AUTOSAR XML (schema 00049)
package /PerceptionApp
  process design PerceptionDesign: executable=perceptiond
package /PerceptionApp/exe
  executable perceptiond: category=APPLICATION_LEVEL, logging-behavior=USES-LOGGING, reporting-behavior=REPORTS-EXECUTION-STATE
    root sw component prototype pc_root: application-type=Perception
package /PerceptionApp/swc
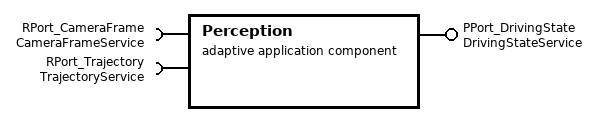
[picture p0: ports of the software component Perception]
  adaptive application sw component type Perception  # Inference and fusion. Produces a lane-relative state and CIPO estimate; produces no command and owns no device.
    require port RPort_CameraFrame: required-interface=CameraFrameService  # Frame descriptors in. The pixels are read from the shared segment this descriptor names, not from the event.
    provide port PPort_DrivingState: provided-interface=DrivingStateService  # Fused state out.
    require port RPort_Trajectory: required-interface=TrajectoryService  # Debug only: lets the visualization overlay draw the plan on the frame it already holds. Not an input to anything perception computes.
